# HC32F558 register map
File version: 1.0
CPU: CM4 r0p1, little endian, MPU, FPU, 4 interrupt priority bits
Registers are 32-bit, read-write, reset 0x0 unless marked. A register's access mark holds for its fields unless they carry their own. Offsets are from the block's base; [hi:lo] are bit positions; {n}, {i} and the like mark numbered series.

## HASH
Base 0x40008400
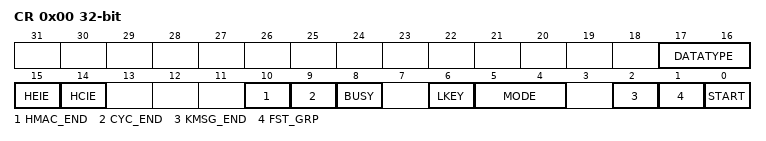
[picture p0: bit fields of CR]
0x00 CR
  [17:16] DATATYPE, [15] HEIE, [14] HCIE, [10] HMAC_END, [9] CYC_END, [8] BUSY, [6] LKEY, [5:4] MODE, [2] KMSG_END, [1] FST_GRP, [0] START
0x10 HR7
0x14 HR6
0x18 HR5
0x1C HR4
0x20 HR3
0x24 HR2
0x28 HR1
0x2C HR0
0x40 DR15
0x44 DR14
0x48 DR13
0x4C DR12
0x50 DR11
0x54 DR10
0x58 DR9
0x5C DR8
0x60 DR7
0x64 DR6
0x68 DR5
0x6C DR4
0x70 DR3
0x74 DR2
0x78 DR1
0x7C DR0

## HRPWM_EMB1 — desc HRPWM_EMB
Base 0x40036400
Same registers: HRPWM_EMB2 0x40036440, HRPWM_EMB3 0x40036480, HRPWM_EMB4 0x400364C0, HRPWM_EMB5 0x40036500, HRPWM_EMB6 0x40036540, HRPWM_EMB7 0x40036580, HRPWM_EMB8 0x400365C0
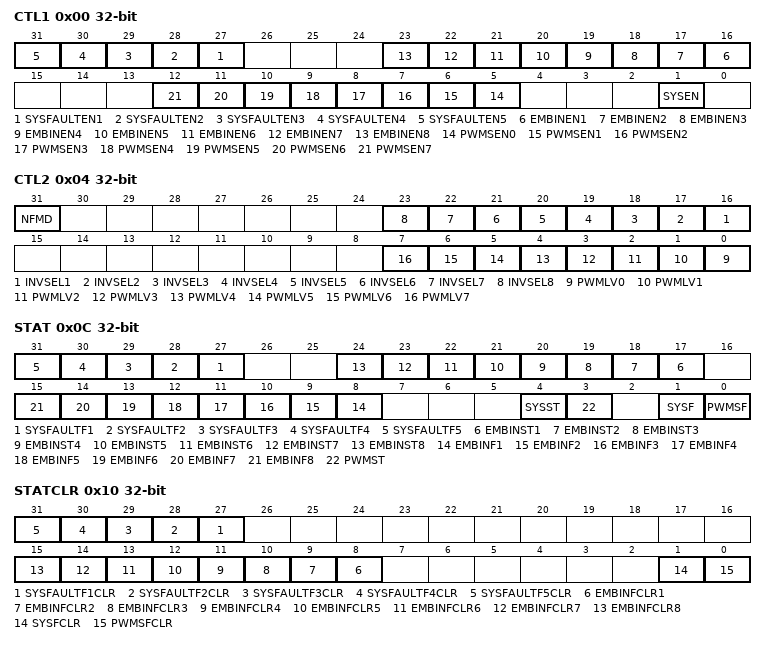
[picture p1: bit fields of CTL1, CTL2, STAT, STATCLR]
0x00 CTL1
  [n+26] SYSFAULTEN{n} (n=1..5), [n+15] EMBINEN{n} (n=1..8), [n+5] PWMSEN{n} (n=0..7), [1] SYSEN
0x04 CTL2
  [31] NFMD, [n+15] INVSEL{n} (n=1..8), [n] PWMLV{n} (n=0..7)
0x08 SOE
  [0] SOE
0x0C STAT ro
  [n+26] SYSFAULTF{n} (n=1..5), [n+16] EMBINST{n} (n=1..8), [n+7] EMBINF{n} (n=1..8), [4] SYSST, [3] PWMST, [1] SYSF, [0] PWMSF
0x10 STATCLR wo
  [n+26] SYSFAULTF{n}CLR (n=1..5), [n+7] EMBINFCLR{n} (n=1..8), [1] SYSFCLR, [0] PWMSFCLR
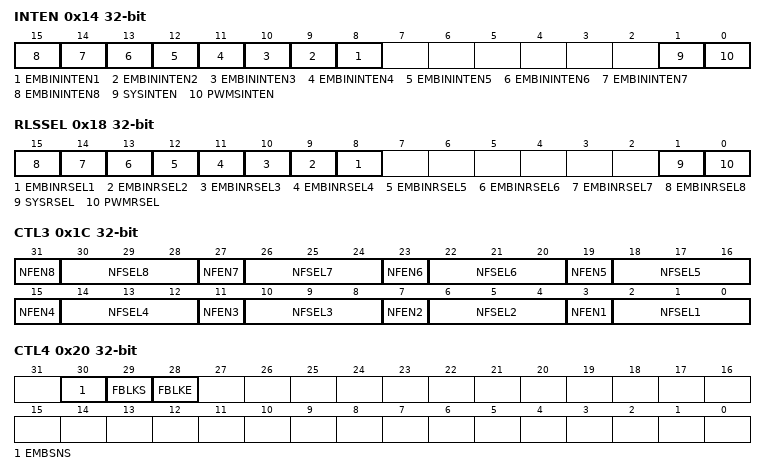
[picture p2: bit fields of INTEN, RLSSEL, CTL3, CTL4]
0x14 INTEN
  [n+7] EMBININTEN{n} (n=1..8), [1] SYSINTEN, [0] PWMSINTEN
0x18 RLSSEL
  [n+7] EMBINRSEL{n} (n=1..8), [1] SYSRSEL, [0] PWMRSEL
0x1C CTL3
  [4n-1] NFEN{n} (n=1..8), [4n-2:4n-4] NFSEL{n} (n=1..8)
0x20 CTL4
  [30] EMBSNS, [29] FBLKS, [28] FBLKE
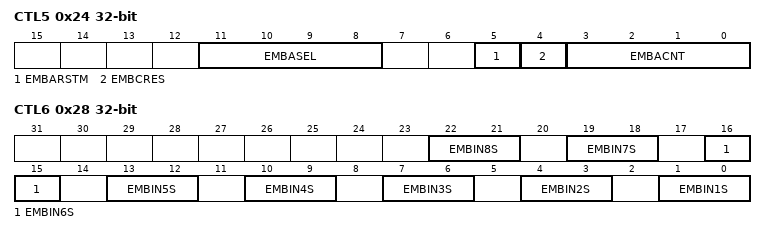
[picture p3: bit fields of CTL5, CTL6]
0x24 CTL5
  [11:8] EMBASEL, [5] EMBARSTM, [4] EMBCRES wo, [3:0] EMBACNT
0x28 CTL6
  [3n-2:3n-3] EMBIN{n}S (n=1..8)

## I2C1 — desc I2C
Base 0x4004E000
Same registers: I2C2 0x4004E400, I2C3 0x4004E800
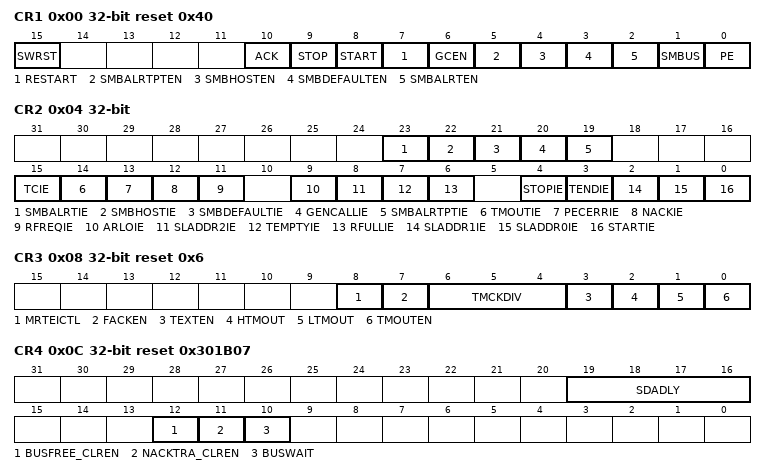
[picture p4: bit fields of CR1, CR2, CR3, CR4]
0x00 CR1 reset 0x40
  [15] SWRST, [10] ACK, [9] STOP, [8] START, [7] RESTART, [6] GCEN, [5] SMBALRTPTEN, [4] SMBHOSTEN, [3] SMBDEFAULTEN, [2] SMBALRTEN, [1] SMBUS, [0] PE
0x04 CR2
  [23] SMBALRTIE, [22] SMBHOSTIE, [21] SMBDEFAULTIE, [20] GENCALLIE, [19] SMBALRTPTIE, [15] TCIE, [14] TMOUTIE, [13] PECERRIE, [12] NACKIE, [11] RFREQIE, [9] ARLOIE, [8] SLADDR2IE, [7] TEMPTYIE, [6] RFULLIE, [4] STOPIE, [3] TENDIE, [2] SLADDR1IE, [1] SLADDR0IE, [0] STARTIE
0x08 CR3 reset 0x6
  [8] MRTEICTL, [7] FACKEN, [6:4] TMCKDIV, [3] TEXTEN, [2] HTMOUT, [1] LTMOUT, [0] TMOUTEN
0x0C CR4 reset 0x301B07
  [19:16] SDADLY, [12] BUSFREE_CLREN, [11] NACKTRA_CLREN, [10] BUSWAIT
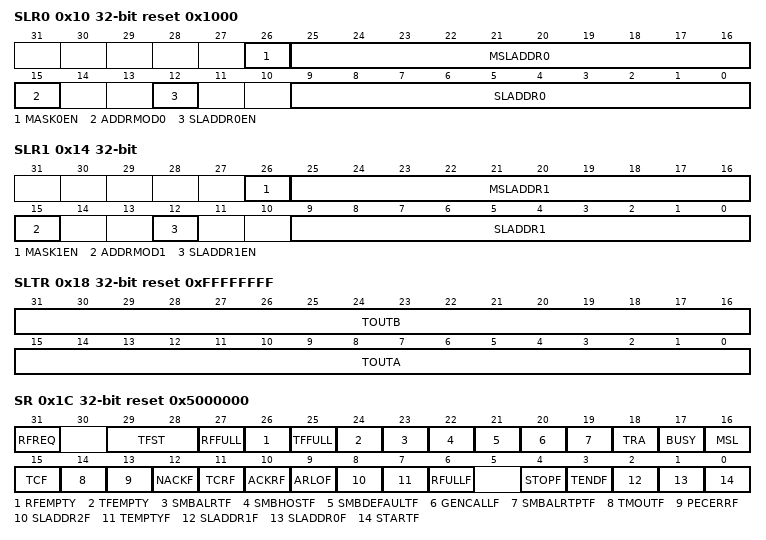
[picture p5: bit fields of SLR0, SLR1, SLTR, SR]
0x10 SLR0 reset 0x1000
  [26] MASK0EN, [25:16] MSLADDR0, [15] ADDRMOD0, [12] SLADDR0EN, [9:0] SLADDR0
0x14 SLR1
  [26] MASK1EN, [25:16] MSLADDR1, [15] ADDRMOD1, [12] SLADDR1EN, [9:0] SLADDR1
0x18 SLTR reset 0xFFFFFFFF
  [31:16] TOUTB, [15:0] TOUTA
0x1C SR reset 0x5000000
  [31] RFREQ ro, [29:28] TFST ro, [27] RFFULL ro, [26] RFEMPTY ro, [25] TFFULL ro, [24] TFEMPTY ro, [23] SMBALRTF ro, [22] SMBHOSTF ro, [21] SMBDEFAULTF ro, [20] GENCALLF ro, [19] SMBALRTPTF ro, [18] TRA, [17] BUSY ro, [16] MSL, [15] TCF ro, [14] TMOUTF ro, [13] PECERRF ro, [12] NACKF ro, [11] TCRF ro, [10] ACKRF ro, [9] ARLOF ro, [8] SLADDR2F ro, [7] TEMPTYF ro, [6] RFULLF ro, [4] STOPF ro, [3] TENDF ro, [2] SLADDR1F ro, [1] SLADDR0F ro, [0] STARTF ro
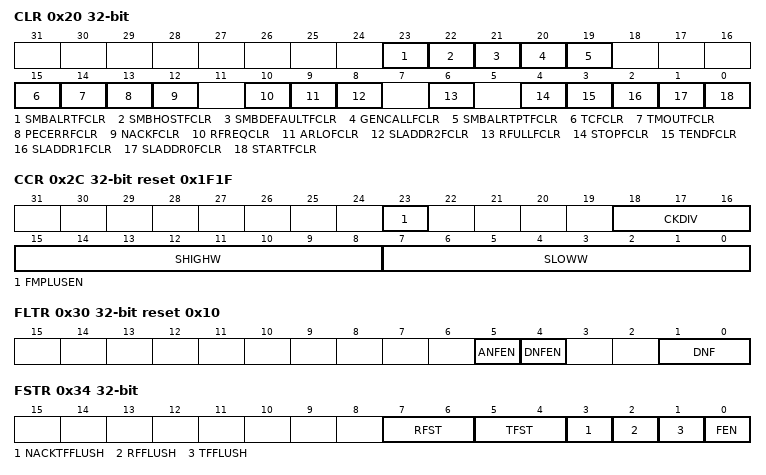
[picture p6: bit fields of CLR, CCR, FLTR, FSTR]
0x20 CLR wo
  [23] SMBALRTFCLR, [22] SMBHOSTFCLR, [21] SMBDEFAULTFCLR, [20] GENCALLFCLR, [19] SMBALRTPTFCLR, [15] TCFCLR, [14] TMOUTFCLR, [13] PECERRFCLR, [12] NACKFCLR, [10] RFREQCLR, [9] ARLOFCLR, [8] SLADDR2FCLR, [6] RFULLFCLR, [4] STOPFCLR, [3] TENDFCLR, [2] SLADDR1FCLR, [1] SLADDR0FCLR, [0] STARTFCLR
0x24 DTR 8-bit reset 0xFF
0x28 DRR 8-bit ro
0x2C CCR reset 0x1F1F
  [23] FMPLUSEN, [18:16] CKDIV, [15:8] SHIGHW, [7:0] SLOWW
0x30 FLTR reset 0x10
  [5] ANFEN, [4] DNFEN, [1:0] DNF
0x34 FSTR
  [7:6] RFST, [5:4] TFST, [3] NACKTFFLUSH, [2] RFFLUSH, [1] TFFLUSH, [0] FEN
0x38 SLVADDR
  [9:0] SLVADR
0x3C PECDR 8-bit
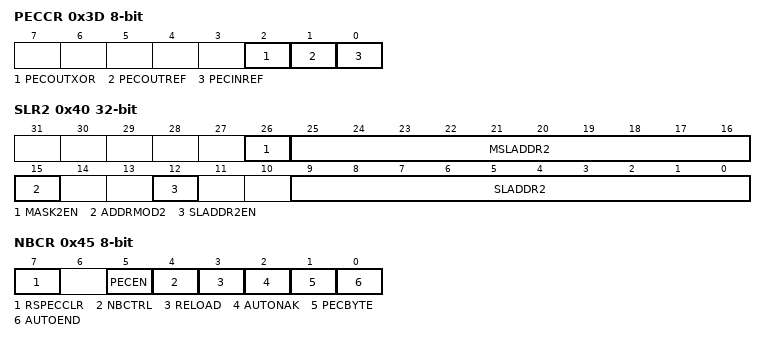
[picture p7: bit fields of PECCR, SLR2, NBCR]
0x3D PECCR 8-bit
  [2] PECOUTXOR, [1] PECOUTREF, [0] PECINREF
0x40 SLR2
  [26] MASK2EN, [25:16] MSLADDR2, [15] ADDRMOD2, [12] SLADDR2EN, [9:0] SLADDR2
0x44 NBYTER 8-bit reset 0xFF
0x45 NBCR 8-bit
  [7] RSPECCLR, [5] PECEN, [4] NBCTRL, [3] RELOAD, [2] AUTONAK, [1] PECBYTE, [0] AUTOEND
